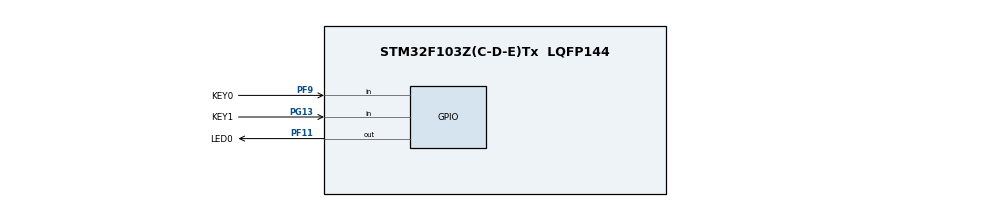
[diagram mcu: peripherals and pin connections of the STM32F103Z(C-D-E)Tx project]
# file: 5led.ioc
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Mcu.Family=STM32F1
Mcu.Name=STM32F103Z(C-D-E)Tx
Mcu.Package=LQFP144
NVIC.PriorityGroup=NVIC_PRIORITYGROUP_4
OSC_IN.Mode=HSE-External-Oscillator
OSC_IN.Signal=RCC_OSC_IN
OSC_OUT.Mode=HSE-External-Oscillator
OSC_OUT.Signal=RCC_OSC_OUT
PA13.Mode=Serial_Wire
PA13.Signal=SYS_JTMS-SWDIO
PA14.Mode=Serial_Wire
PA14.Signal=SYS_JTCK-SWCLK
PC14-OSC32_IN.Mode=LSE-External-Oscillator
PC14-OSC32_IN.Signal=RCC_OSC32_IN
PC15-OSC32_OUT.Mode=LSE-External-Oscillator
PC15-OSC32_OUT.Signal=RCC_OSC32_OUT
PF11.GPIO_Label=LED0
PF11.Signal=GPIO_Output
PF9.GPIO_Label=KEY0
PF9.GPIO_PuPd=GPIO_PULLUP
PF9.Signal=GPIO_Input
PG13.GPIO_Label=KEY1
PG13.GPIO_PuPd=GPIO_PULLUP
PG13.Signal=GPIO_Input
ProjectManager.HeapSize=0x200
ProjectManager.StackSize=0x400
ProjectManager.TargetToolchain=MDK-ARM V5.27
RCC.APB1Freq_Value=8000000
RCC.APB2Freq_Value=8000000
board=custom

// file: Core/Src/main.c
/* USER CODE BEGIN Header */
/**
  ******************************************************************************
  * @file           : main.c
  * @brief          : Main program body
  ******************************************************************************
  * @attention
  *
  * <h2><center>&copy; Copyright (c) 2021 STMicroelectronics.
  * All rights reserved.</center></h2>
  *
  * This software component is licensed by ST under BSD 3-Clause license,
  * the "License"; You may not use this file except in compliance with the
  * License. You may obtain a copy of the License at:
  *                        opensource.org/licenses/BSD-3-Clause
  *
  ******************************************************************************
  */
/* USER CODE END Header */
#include "main.h"
#include "gpio.h"

void SystemClock_Config(void);
/* USER CODE BEGIN PFP */
uint8_t Key_Scan(uint8_t mode){
	static uint8_t key_up=1;//按键按松开标志
	if(mode)key_up=1;  //支持连按
	if(key_up&&(HAL_GPIO_ReadPin(KEY0_GPIO_Port,KEY0_Pin)==0||HAL_GPIO_ReadPin(KEY1_GPIO_Port,KEY1_Pin)==0))
	{
		int a=10000;
		while(a--);
		key_up=0;
		if(HAL_GPIO_ReadPin(KEY0_GPIO_Port,KEY0_Pin)==0)return 1;
		else if(HAL_GPIO_ReadPin(KEY1_GPIO_Port,KEY1_Pin)==0)return 2;
	}else if(HAL_GPIO_ReadPin(KEY0_GPIO_Port,KEY0_Pin)==1&&HAL_GPIO_ReadPin(KEY1_GPIO_Port,KEY1_Pin)==1)key_up=1;
 	return 0;// 无按键按下
}
/* USER CODE END PFP */

int main(void)
{

  /* MCU Configuration--------------------------------------------------------*/

  /* Reset of all peripherals, Initializes the Flash interface and the Systick. */
  HAL_Init();

  /* Configure the system clock */
  SystemClock_Config();

  /* Initialize all configured peripherals */
  MX_GPIO_Init();

  /* Infinite loop */
  while (1)
  {
		uint8_t key = Key_Scan(0);
		switch(key){
			case 1:
				HAL_GPIO_TogglePin(LED0_GPIO_Port,LED0_Pin);
				break;
			case 2:
				HAL_GPIO_TogglePin(LED0_GPIO_Port,LED0_Pin);
				break;

		}
  }
}

void SystemClock_Config(void)
{
  RCC_OscInitTypeDef RCC_OscInitStruct = {0};
  RCC_ClkInitTypeDef RCC_ClkInitStruct = {0};

  /** Initializes the RCC Oscillators according to the specified parameters
  * in the RCC_OscInitTypeDef structure.
  */
  RCC_OscInitStruct.OscillatorType = RCC_OSCILLATORTYPE_HSI;
  RCC_OscInitStruct.HSIState = RCC_HSI_ON;
  RCC_OscInitStruct.HSICalibrationValue = RCC_HSICALIBRATION_DEFAULT;
  RCC_OscInitStruct.PLL.PLLState = RCC_PLL_NONE;
  if (HAL_RCC_OscConfig(&RCC_OscInitStruct) != HAL_OK)
  {
    Error_Handler();
  }
  /** Initializes the CPU, AHB and APB buses clocks
  */
  RCC_ClkInitStruct.ClockType = RCC_CLOCKTYPE_HCLK|RCC_CLOCKTYPE_SYSCLK
                              |RCC_CLOCKTYPE_PCLK1|RCC_CLOCKTYPE_PCLK2;
  RCC_ClkInitStruct.SYSCLKSource = RCC_SYSCLKSOURCE_HSI;
  RCC_ClkInitStruct.AHBCLKDivider = RCC_SYSCLK_DIV1;
  RCC_ClkInitStruct.APB1CLKDivider = RCC_HCLK_DIV1;
  RCC_ClkInitStruct.APB2CLKDivider = RCC_HCLK_DIV1;

  if (HAL_RCC_ClockConfig(&RCC_ClkInitStruct, FLASH_LATENCY_0) != HAL_OK)
  {
    Error_Handler();
  }
}

void Error_Handler(void)
{
  __disable_irq();
  while (1)
  {
  }
}

/************************ (C) COPYRIGHT STMicroelectronics *****END OF FILE****/
